VERSION ""

NS_ :

BS_:

BU_:

BO_ 256 BMS_Tel: 1 Vector__XXX
 SG_ Cur_con : 2|1@1+ (1,0) [0|1] "" Vector__XXX
 SG_ Vol_con : 0|2@1+ (1,0) [0|2] "" Vector__XXX

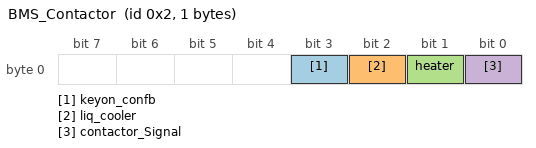
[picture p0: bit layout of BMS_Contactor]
BO_ 2 BMS_Contactor: 1 Vector__XXX
 SG_ keyon_confb : 3|1@1+ (1,0) [0|1] "" Vector__XXX
 SG_ liq_cooler : 2|1@1+ (1,0) [0|1] "" Vector__XXX
 SG_ heater : 1|1@1+ (1,0) [0|1] "" Vector__XXX
 SG_ contactor_Signal : 0|1@1+ (1,0) [0|1] "" Vector__XXX

BO_ 1 airbag: 1 Vector__XXX
 SG_ airbag_Signal_1 : 0|1@1+ (1,0) [0|1] "" Vector__XXX

BA_DEF_ BO_  "CANFD_BRS" ENUM  "0","1";
BA_DEF_  "DBName" STRING ;
BA_DEF_  "BusType" STRING ;
BA_DEF_ BO_  "VFrameFormat" ENUM  "StandardCAN","ExtendedCAN","reserved","reserved","reserved","reserved","reserved","reserved","reserved","reserved","reserved","reserved","reserved","reserved","StandardCAN_FD","ExtendedCAN_FD";
BA_DEF_DEF_  "CANFD_BRS" "1";
BA_DEF_DEF_  "DBName" "";
BA_DEF_DEF_  "BusType" "";
BA_DEF_DEF_  "VFrameFormat" "StandardCAN";
BA_ "BusType" "CAN FD";
BA_ "DBName" "BMSdb";
